AUTOSAR XML (schema 00051)
package /Components
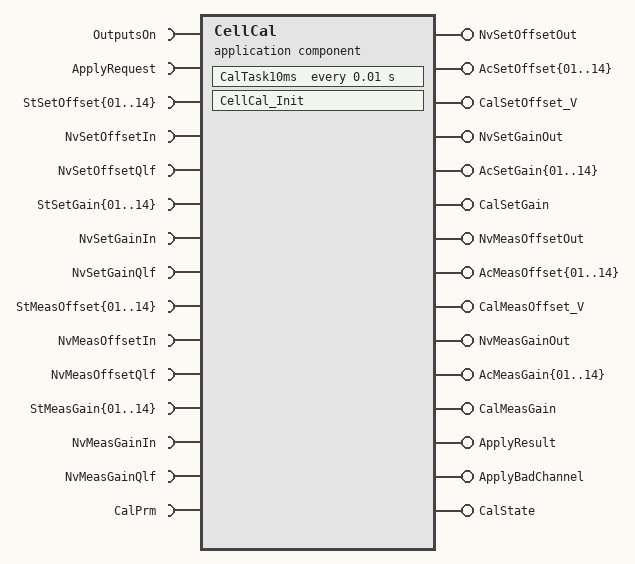
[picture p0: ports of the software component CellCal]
  application sw component type CellCal
    66 x require port:
      OutputsOn: nonqueued-receiver-com-spec{data-element=OutputsOn, init-value=0}, required-interface=OutputsOn
      ApplyRequest: nonqueued-receiver-com-spec{data-element=ApplyRequest, init-value=0}, required-interface=ApplyRequest
      StSetOffset{01..14}: nonqueued-receiver-com-spec{data-element=StSetOffset{01..14}, init-value=0}, required-interface=StSetOffset{01..14}
      NvSetOffsetIn: nonqueued-receiver-com-spec{data-element=NvSetOffsetIn, init-value=14 x 0}, required-interface=NvSetOffsetIn
      NvSetOffsetQlf: nonqueued-receiver-com-spec{data-element=NvSetOffsetQlf, init-value=0}, required-interface=NvSetOffsetQlf
      StSetGain{01..14}: nonqueued-receiver-com-spec{data-element=StSetGain{01..14}, init-value=0}, required-interface=StSetGain{01..14}
      NvSetGainIn: nonqueued-receiver-com-spec{data-element=NvSetGainIn, init-value=14 x 0}, required-interface=NvSetGainIn
      NvSetGainQlf: nonqueued-receiver-com-spec{data-element=NvSetGainQlf, init-value=0}, required-interface=NvSetGainQlf
      StMeasOffset{01..14}: nonqueued-receiver-com-spec{data-element=StMeasOffset{01..14}, init-value=0}, required-interface=StMeasOffset{01..14}
      NvMeasOffsetIn: nonqueued-receiver-com-spec{data-element=NvMeasOffsetIn, init-value=14 x 0}, required-interface=NvMeasOffsetIn
      NvMeasOffsetQlf: nonqueued-receiver-com-spec{data-element=NvMeasOffsetQlf, init-value=0}, required-interface=NvMeasOffsetQlf
      StMeasGain{01..14}: nonqueued-receiver-com-spec{data-element=StMeasGain{01..14}, init-value=0}, required-interface=StMeasGain{01..14}
      NvMeasGainIn: nonqueued-receiver-com-spec{data-element=NvMeasGainIn, init-value=14 x 0}, required-interface=NvMeasGainIn
      NvMeasGainQlf: nonqueued-receiver-com-spec{data-element=NvMeasGainQlf, init-value=0}, required-interface=NvMeasGainQlf
    67 x provide port:
      NvSetOffsetOut: nonqueued-sender-com-spec{data-element=NvSetOffsetOut, init-value=14 x 0}, provided-interface=NvSetOffsetOut
      AcSetOffset{01..14}: nonqueued-sender-com-spec{data-element=AcSetOffset{01..14}, init-value=0}, provided-interface=AcSetOffset{01..14}
      CalSetOffset_V: nonqueued-sender-com-spec{data-element=CalSetOffset_V, init-value=14 x 0}, provided-interface=CalSetOffset_V
      NvSetGainOut: nonqueued-sender-com-spec{data-element=NvSetGainOut, init-value=14 x 0}, provided-interface=NvSetGainOut
      AcSetGain{01..14}: nonqueued-sender-com-spec{data-element=AcSetGain{01..14}, init-value=0}, provided-interface=AcSetGain{01..14}
      CalSetGain: nonqueued-sender-com-spec{data-element=CalSetGain, init-value=14 x 0}, provided-interface=CalSetGain
      NvMeasOffsetOut: nonqueued-sender-com-spec{data-element=NvMeasOffsetOut, init-value=14 x 0}, provided-interface=NvMeasOffsetOut
      AcMeasOffset{01..14}: nonqueued-sender-com-spec{data-element=AcMeasOffset{01..14}, init-value=0}, provided-interface=AcMeasOffset{01..14}
      CalMeasOffset_V: nonqueued-sender-com-spec{data-element=CalMeasOffset_V, init-value=14 x 0}, provided-interface=CalMeasOffset_V
      NvMeasGainOut: nonqueued-sender-com-spec{data-element=NvMeasGainOut, init-value=14 x 0}, provided-interface=NvMeasGainOut
      AcMeasGain{01..14}: nonqueued-sender-com-spec{data-element=AcMeasGain{01..14}, init-value=0}, provided-interface=AcMeasGain{01..14}
      CalMeasGain: nonqueued-sender-com-spec{data-element=CalMeasGain, init-value=14 x 0}, provided-interface=CalMeasGain
      ApplyResult: nonqueued-sender-com-spec{data-element=ApplyResult, init-value=0}, provided-interface=ApplyResult
      ApplyBadChannel: nonqueued-sender-com-spec{data-element=ApplyBadChannel, init-value=0}, provided-interface=ApplyBadChannel
      CalState: nonqueued-sender-com-spec{data-element=CalState, init-value=0}, provided-interface=CalState
    require port CalPrm: required-interface=CalPrm
      required-com-specs:
        init-value=CalPrm_GainMax_code:11000, parameter=GainMax_code
        init-value=CalPrm_GainMin_code:9000, parameter=GainMin_code
        init-value=CalPrm_OffsetLimit_code:2000, parameter=OffsetLimit_code
    behavior CellCal_IB: handle-termination-and-restart=NO-SUPPORT
      timing event Event_CalTask10ms: start-on-event=CalTask10ms, period=0.01
      runnable CellCal_Init
      runnable CalTask10ms
        data-receive-point-by-arguments:
          66 x access:
            IN_ApplyRequest_ApplyRequest: accessed-variable=ApplyRequest.ApplyRequest
            IN_NvMeasGainIn_NvMeasGainIn: accessed-variable=NvMeasGainIn.NvMeasGainIn
            IN_NvMeasGainQlf_NvMeasGainQlf: accessed-variable=NvMeasGainQlf.NvMeasGainQlf
            IN_NvMeasOffsetIn_NvMeasOffsetIn: accessed-variable=NvMeasOffsetIn.NvMeasOffsetIn
            IN_NvMeasOffsetQlf_NvMeasOffsetQlf: accessed-variable=NvMeasOffsetQlf.NvMeasOffsetQlf
            IN_NvSetGainIn_NvSetGainIn: accessed-variable=NvSetGainIn.NvSetGainIn
            IN_NvSetGainQlf_NvSetGainQlf: accessed-variable=NvSetGainQlf.NvSetGainQlf
            IN_NvSetOffsetIn_NvSetOffsetIn: accessed-variable=NvSetOffsetIn.NvSetOffsetIn
            IN_NvSetOffsetQlf_NvSetOffsetQlf: accessed-variable=NvSetOffsetQlf.NvSetOffsetQlf
            IN_OutputsOn_OutputsOn: accessed-variable=OutputsOn.OutputsOn
            IN_StMeasGain{01..14}_StMeasGain{01..14}: accessed-variable=StMeasGain{01..14}.StMeasGain{01..14}
            IN_StMeasOffset{01..14}_StMeasOffset{01..14}: accessed-variable=StMeasOffset{01..14}.StMeasOffset{01..14}
            IN_StSetGain{01..14}_StSetGain{01..14}: accessed-variable=StSetGain{01..14}.StSetGain{01..14}
            IN_StSetOffset{01..14}_StSetOffset{01..14}: accessed-variable=StSetOffset{01..14}.StSetOffset{01..14}
        data-send-points:
          67 x access:
            OUT_NvSetOffsetOut_NvSetOffsetOut: accessed-variable=NvSetOffsetOut.NvSetOffsetOut
            OUT_AcSetOffset{01..14}_AcSetOffset{01..14}: accessed-variable=AcSetOffset{01..14}.AcSetOffset{01..14}
            OUT_CalSetOffset_V_CalSetOffset_V: accessed-variable=CalSetOffset_V.CalSetOffset_V
            OUT_NvSetGainOut_NvSetGainOut: accessed-variable=NvSetGainOut.NvSetGainOut
            OUT_AcSetGain{01..14}_AcSetGain{01..14}: accessed-variable=AcSetGain{01..14}.AcSetGain{01..14}
            OUT_CalSetGain_CalSetGain: accessed-variable=CalSetGain.CalSetGain
            OUT_NvMeasOffsetOut_NvMeasOffsetOut: accessed-variable=NvMeasOffsetOut.NvMeasOffsetOut
            OUT_AcMeasOffset{01..14}_AcMeasOffset{01..14}: accessed-variable=AcMeasOffset{01..14}.AcMeasOffset{01..14}
            OUT_CalMeasOffset_V_CalMeasOffset_V: accessed-variable=CalMeasOffset_V.CalMeasOffset_V
            OUT_NvMeasGainOut_NvMeasGainOut: accessed-variable=NvMeasGainOut.NvMeasGainOut
            OUT_AcMeasGain{01..14}_AcMeasGain{01..14}: accessed-variable=AcMeasGain{01..14}.AcMeasGain{01..14}
            OUT_CalMeasGain_CalMeasGain: accessed-variable=CalMeasGain.CalMeasGain
            OUT_ApplyResult_ApplyResult: accessed-variable=ApplyResult.ApplyResult
            OUT_ApplyBadChannel_ApplyBadChannel: accessed-variable=ApplyBadChannel.ApplyBadChannel
            OUT_CalState_CalState: accessed-variable=CalState.CalState
        parameter access CALPRM_CalPrm_GainMax_code: accessed-parameter=CalPrm.GainMax_code
        parameter access CALPRM_CalPrm_GainMin_code: accessed-parameter=CalPrm.GainMin_code
        parameter access CALPRM_CalPrm_OffsetLimit_code: accessed-parameter=CalPrm.OffsetLimit_code
      variation point proxy CellCount: category=VALUE, value-access=integer-value-variation-point=CellCount
